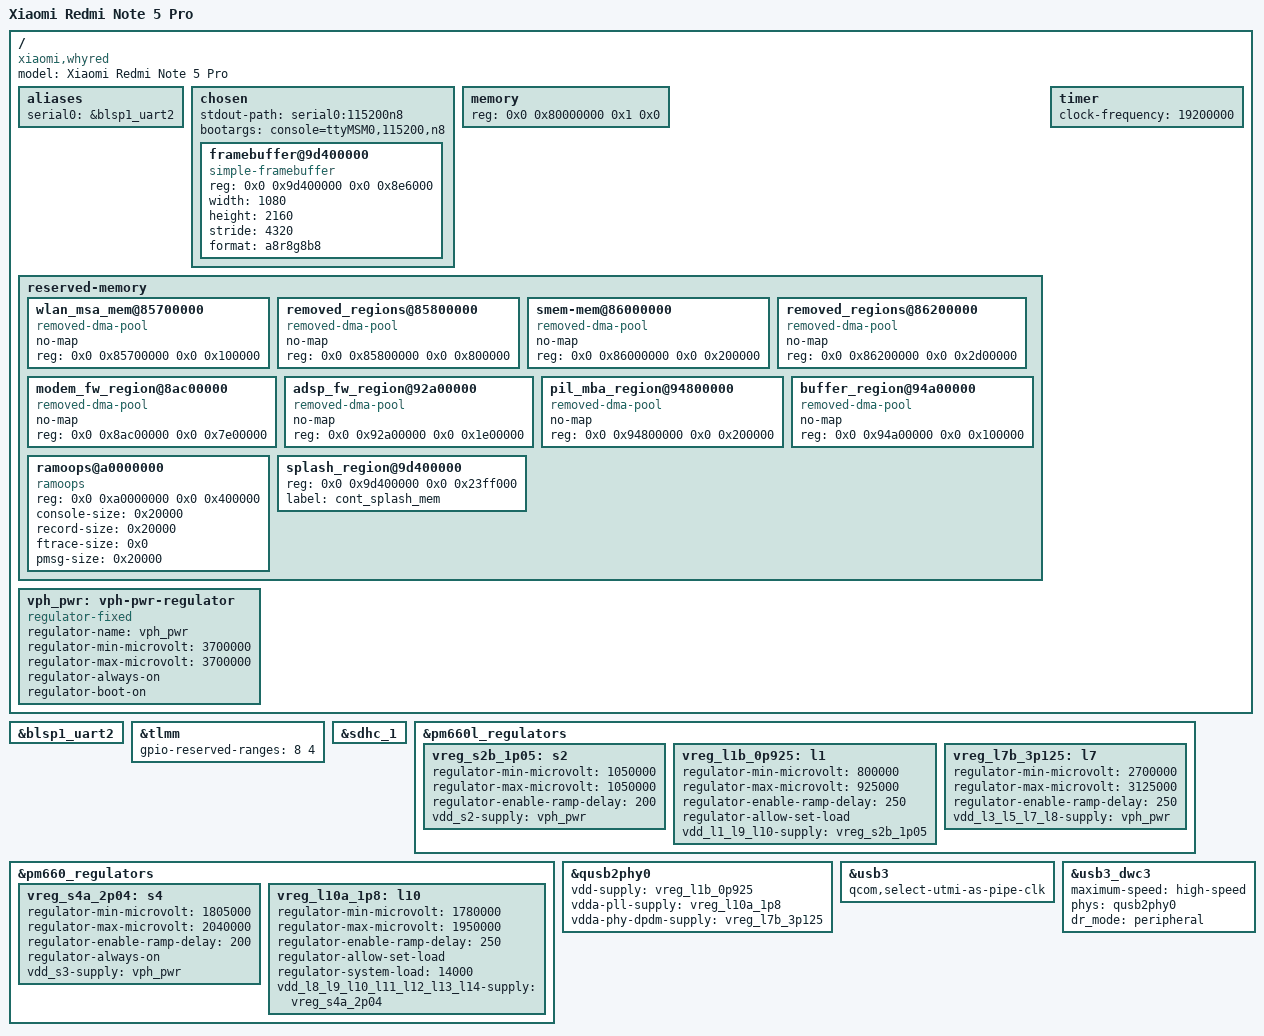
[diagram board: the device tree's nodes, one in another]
// SPDX-License-Identifier: GPL-2.0-only
/*
 * Copyright (c) 2020, Alexey Minnekhanov <alexey.min@gmail.com>
 * Copyright (c) 2020, Martin Botka
 *
 * Xiaomi Redmi Note 5 Pro (whyred) - SDM636.
 * Based on sdm660-xiaomi-lavender.dts and
 * sdm636-sony-xperia-ganges-mermaid.dts.
 *
 * Ported to the Android Common Kernel (android12-5.10) from
 * the CIP 5.10 port. The device tree is carried over as-is:
 * sdhc_1 enabled, ramoops for the boot log, a /memory
 * placeholder and bootargs placeholder matching the CAF DTB,
 * pm660/pm660l includes, and a simple-framebuffer console
 * on the bootloader splash (0x9d400000, 1080x2160) so the
 * boot log is visible on the display. The CIP port never
 * booted (stuck at the logo, empty pstore, in all seven
 * milestones), so this ACK base is tried instead.
 */

/dts-v1/;

#include "sdm630.dtsi"
#include "pm660.dtsi"
#include "pm660l.dtsi"

/ {
	model = "Xiaomi Redmi Note 5 Pro";
	compatible = "xiaomi,whyred", "qcom,sdm636";

	aliases {
		serial0 = &blsp1_uart2;
	};

	chosen {
		stdout-path = "serial0:115200n8";
		/* Placeholder cmdline, like the CAF DTB: the bootloader
		 * overwrites bootargs with the boot image cmdline.
		 * If it does not, the kernel still gets a console. */
		bootargs = "console=ttyMSM0,115200,n8";
		#address-cells = <2>;
		#size-cells = <2>;
		ranges;

		/* Bootloader splash framebuffer, 1080x2160x32bpp.
		 * simplefb + fbcon render the kernel log on screen. */
		framebuffer@9d400000 {
			compatible = "simple-framebuffer";
			reg = <0x0 0x9d400000 0x0 0x8e6000>;
			width = <1080>;
			height = <2160>;
			stride = <4320>;
			format = "a8r8g8b8";
			status = "okay";
		};
	};

	/* Placeholder memory node, like the CAF DTB: the bootloader
	 * fills reg with the real RAM base/size. Without this node
	 * the kernel may boot with no memory described at all. */
	/* RAM is hard-coded instead of relying on the bootloader to fill
	 * this placeholder: if LK leaves reg as 0,0,0,0 the kernel sees
	 * no memory at all and hangs in setup_arch before any breadcrumb
	 * can be written. 4 GB at 0x80000000; LK overwrites this with the
	 * real size when it does fill the node, and 4 GB is safe on both
	 * the 4 GB and 6 GB whyred variants (the kernel just sees less
	 * RAM on a 6 GB unit). */
	memory {
		device_type = "memory";
		reg = <0x0 0x80000000 0x1 0x0>;
	};

	reserved-memory {
		#address-cells = <2>;
		#size-cells = <2>;
		ranges;

		/* Firmware carveouts, copied from the CAF DTB. Without these
		 * the kernel treats modem/DSP/SMEM memory as free RAM and
		 * may allocate it, corrupting firmware or its own data. */
		wlan_msa_mem@85700000 {
			compatible = "removed-dma-pool";
			no-map;
			reg = <0x0 0x85700000 0x0 0x100000>;
		};

		removed_regions@85800000 {
			compatible = "removed-dma-pool";
			no-map;
			reg = <0x0 0x85800000 0x0 0x800000>;
		};

		smem-mem@86000000 {
			compatible = "removed-dma-pool";
			no-map;
			reg = <0x0 0x86000000 0x0 0x200000>;
		};

		removed_regions@86200000 {
			compatible = "removed-dma-pool";
			no-map;
			reg = <0x0 0x86200000 0x0 0x2d00000>;
		};

		modem_fw_region@8ac00000 {
			compatible = "removed-dma-pool";
			no-map;
			reg = <0x0 0x8ac00000 0x0 0x7e00000>;
		};

		adsp_fw_region@92a00000 {
			compatible = "removed-dma-pool";
			no-map;
			reg = <0x0 0x92a00000 0x0 0x1e00000>;
		};

		pil_mba_region@94800000 {
			compatible = "removed-dma-pool";
			no-map;
			reg = <0x0 0x94800000 0x0 0x200000>;
		};

		buffer_region@94a00000 {
			compatible = "removed-dma-pool";
			no-map;
			reg = <0x0 0x94a00000 0x0 0x100000>;
		};

		ramoops@a0000000 {
			compatible = "ramoops";
			reg = <0x0 0xa0000000 0x0 0x400000>;
			console-size = <0x20000>;
			record-size = <0x20000>;
			ftrace-size = <0x0>;
			pmsg-size = <0x20000>;
		};

		/* Bootloader splash framebuffer region, from the CAF DTB. */
		splash_region@9d400000 {
			reg = <0x0 0x9d400000 0x0 0x23ff000>;
			label = "cont_splash_mem";
		};
	};

	/* Battery / system rail, 3.7 V. Input rail for the PMIC
	 * regulators; the bootloader already powers it. */
	vph_pwr: vph-pwr-regulator {
		compatible = "regulator-fixed";
		regulator-name = "vph_pwr";
		regulator-min-microvolt = <3700000>;
		regulator-max-microvolt = <3700000>;

		regulator-always-on;
		regulator-boot-on;
	};
};

&blsp1_uart2 {
	status = "okay";
};

&tlmm {
	gpio-reserved-ranges = <8 4>;
};

&sdhc_1 {
	status = "okay";
};

/* PMIC regulators for the USB PHY supply chain, values from
 * mainline. These are SPMI regulators (qcom_spmi-regulator);
 * the RPM regulator driver in this kernel has no pm660 data,
 * so the mainline &rpm_requests nodes are not used. The l7
 * input is fed from vph_pwr instead of the boost (bob)
 * regulator, which the SPMI driver does not implement. */
&pm660l_regulators {
	vreg_s2b_1p05: s2 {
		regulator-min-microvolt = <1050000>;
		regulator-max-microvolt = <1050000>;
		regulator-enable-ramp-delay = <200>;
		vdd_s2-supply = <&vph_pwr>;
	};

	vreg_l1b_0p925: l1 {
		regulator-min-microvolt = <800000>;
		regulator-max-microvolt = <925000>;
		regulator-enable-ramp-delay = <250>;
		regulator-allow-set-load;
		vdd_l1_l9_l10-supply = <&vreg_s2b_1p05>;
	};

	vreg_l7b_3p125: l7 {
		regulator-min-microvolt = <2700000>;
		regulator-max-microvolt = <3125000>;
		regulator-enable-ramp-delay = <250>;
		vdd_l3_l5_l7_l8-supply = <&vph_pwr>;
	};
};

&pm660_regulators {
	vreg_s4a_2p04: s4 {
		regulator-min-microvolt = <1805000>;
		regulator-max-microvolt = <2040000>;
		regulator-enable-ramp-delay = <200>;
		regulator-always-on;
		vdd_s3-supply = <&vph_pwr>;
	};

	vreg_l10a_1p8: l10 {
		regulator-min-microvolt = <1780000>;
		regulator-max-microvolt = <1950000>;
		regulator-enable-ramp-delay = <250>;
		regulator-allow-set-load;
		regulator-system-load = <14000>;
		vdd_l8_l9_l10_l11_l12_l13_l14-supply = <&vreg_s4a_2p04>;
	};
};

&qusb2phy0 {
	vdd-supply = <&vreg_l1b_0p925>;
	vdda-pll-supply = <&vreg_l10a_1p8>;
	vdda-phy-dpdm-supply = <&vreg_l7b_3p125>;

	status = "okay";
};

&usb3 {
	qcom,select-utmi-as-pipe-clk;

	status = "okay";
};

&usb3_dwc3 {
	maximum-speed = "high-speed";
	phys = <&qusb2phy0>;
	phy-names = "usb2-phy";
	dr_mode = "peripheral";
};

/ {
	/* The bootloader (LK) does not set CNTFRQ_EL0 on whyred, so the
	 * architected timer has no frequency without this. Without a
	 * frequency, arch_timer fails to initialise, no timer interrupt
	 * ever fires, and calibrate_delay() spins forever waiting for a
	 * jiffy -- the phone hangs on the logo before any initcall.
	 * 19200000 Hz (19.2 MHz XO) matches the CAF DTB value. */
	timer {
		clock-frequency = <19200000>;
	};
};
